# PY32F030xx register map
Vendor: Puya; Series: PY32F0; File version: 1.0.0
CPU: CM0+ r0p1, little endian, no MPU, no FPU, 4 interrupt priority bits
Registers are 32-bit, read-write, reset 0x0 unless marked. A register's access mark holds for its fields unless they carry their own. Offsets are from the block's base; [hi:lo] are bit positions.

## SPI1 — Serial peripheral interface
Base 0x40013000
Same registers: SPI2 0x40003800
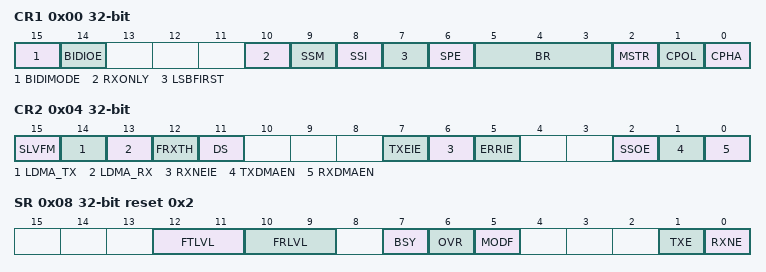
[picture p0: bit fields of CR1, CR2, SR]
0x00 CR1 — control register 1
  [15] BIDIMODE — Bidirectional data mode enable
    0=Unidirectional (2-line unidirectional data mode selected); 1=Bidirectional (1-line bidirectional data mode selected)
  [14] BIDIOE — Output enable in bidirectional mode
    0=Output disabled (receive-only mode); 1=Output enabled (transmit-only mode)
  [10] RXONLY — Receive only
    0=Full duplex (Transmit and receive); 1=Output disabled (Receive-only mode)
  [9] SSM — Software slave management
    0=Disabled (Software slave management disabled); 1=Enabled (Software slave management enabled)
  [8] SSI — Internal slave selection
    0=SlaveSelected (0 is forced onto the NSS pin and the I/O value of the NSS pin is ignored); 1=SlaveNotSelected (1 is forced onto the NSS pin and the I/O value of the NSS pin is ignored)
  [7] LSBFIRST — Frame format
    0=MSBFirst (Data is transmitted/received with the MSB first); 1=LSBFirst (Data is transmitted/received with the LSB first)
  [6] SPE — SPI enable
    0=Disabled (Peripheral disabled); 1=Enabled (Peripheral enabled)
  [5:3] BR — Baud rate control
    0=Div2 (f_PCLK / 2); 1=Div4 (f_PCLK / 4); 2=Div8 (f_PCLK / 8); 3=Div16 (f_PCLK / 16); 4=Div32 (f_PCLK / 32); 5=Div64 (f_PCLK / 64); 6=Div128 (f_PCLK / 128); 7=Div256 (f_PCLK / 256)
  [2] MSTR — Master selection
    0=Slave configuration; 1=Master configuration
  [1] CPOL — Clock polarity
    0=IdleLow (CK to 0 when idle); 1=IdleHigh (CK to 1 when idle)
  [0] CPHA — Clock phase
    0=FirstEdge (The first clock transition is the first data capture edge); 1=SecondEdge (The second clock transition is the first data capture edge)
0x04 CR2 — control register 2
  [15] SLVFM — Slave fast mode enable
    0=Normal (Slave normal mode, spi clock speed less than PCLK / 4); 1=Fast (Slave fast mode, spi clock speed equal to PCLK / 4)
  [14] LDMA_TX — Last DAM Transmit(TX)
    0=Even (Number of data to transfer for transmit is even); 1=Odd (Number of data to transfer for transmit is odd)
  [13] LDMA_RX — Last DAM Transmit(RX)
    0=Even (Number of data to transfer for receive is even); 1=Odd (Number of data to transfer for receive is odd)
  [12] FRXTH — FIFO reception threshold
    0=Half (RXNE event is generated if the FIFO level is greater than or equal to 1/2 (16-bit)); 1=Quarter (RXNE event is generated if the FIFO level is greater than or equal to 1/4 (8-bit))
  [11] DS — Data length
    0=EightBit (8-bit); 1=SixteenBit (16-bit)
  [7] TXEIE — Tx buffer empty interrupt enable
    0=Masked (TXE interrupt masked); 1=NotMasked (TXE interrupt not masked)
  [6] RXNEIE — RX buffer not empty interrupt enable
    0=Masked (RXE interrupt masked); 1=NotMasked (RXE interrupt not masked)
  [5] ERRIE — Error interrupt enable
    0=Masked (Error interrupt masked); 1=NotMasked (Error interrupt not masked)
  [2] SSOE — SS output enable
    0=Disabled (SS output is disabled in master mode); 1=Enabled (SS output is enabled in master mode)
  [1] TXDMAEN — Tx buffer DMA enable
    0=Disabled (Tx buffer DMA disabled); 1=Enabled (Tx buffer DMA enabled)
  [0] RXDMAEN — Rx buffer DMA enable
    0=Disabled (Rx buffer DMA disabled); 1=Enabled (Rx buffer DMA enabled)
0x08 SR reset 0x2 — status register
  [12:11] FTLVL ro — FIFO transmission level
    0=Empty (Tx FIFO Empty); 1=Quarter (Tx 1/4 FIFO); 2=Half (Tx 1/2 FIFO); 3=Full (Tx FIFO full)
  [10:9] FRLVL ro — FIFO reception level
    0=Empty (Rx FIFO Empty); 1=Quarter (Rx 1/4 FIFO); 2=Half (Rx 1/2 FIFO); 3=Full (Rx FIFO full)
  [7] BSY ro — Busy flag
    0=NotBusy (SPI not busy); 1=Busy (SPI busy)
  [6] OVR ro — Overrun flag
    0=No overrun occurred; 1=Overrun occurred
  [5] MODF ro — Mode fault
    0=NoFault (No mode fault occurred); 1=Fault (Mode fault occurred)
  [1] TXE ro — Transmit buffer empty
    0=NotEmpty (Tx buffer not empty); 1=Empty (Tx buffer empty)
  [0] RXNE ro — Receive buffer not empty
    0=Empty (Rx buffer empty); 1=NotEmpty (Rx buffer not empty)
0x0C DR — data register
  [15:0] DR — Data register
0x0C DR8 8-bit (alternate view of DR) — Direct 8-bit access to data register
  [7:0] DR — Data register
